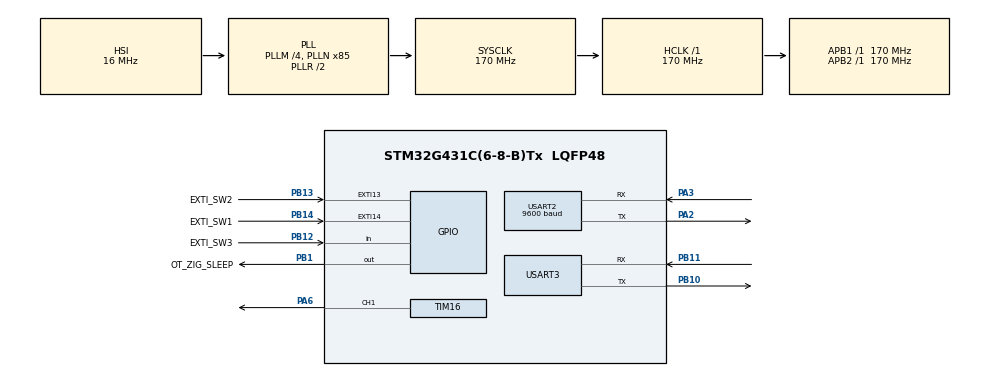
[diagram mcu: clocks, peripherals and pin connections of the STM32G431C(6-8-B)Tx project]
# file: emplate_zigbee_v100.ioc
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Dma.Request0=USART2_RX
Dma.Request1=USART2_TX
Dma.USART2_RX.0.Direction=DMA_PERIPH_TO_MEMORY
Dma.USART2_RX.0.EventEnable=DISABLE
Dma.USART2_RX.0.Instance=DMA1_Channel1
Dma.USART2_RX.0.MemDataAlignment=DMA_MDATAALIGN_BYTE
Dma.USART2_RX.0.MemInc=DMA_MINC_ENABLE
Dma.USART2_RX.0.Mode=DMA_CIRCULAR
Dma.USART2_RX.0.PeriphDataAlignment=DMA_PDATAALIGN_BYTE
Dma.USART2_RX.0.PeriphInc=DMA_PINC_DISABLE
Dma.USART2_RX.0.Polarity=HAL_DMAMUX_REQ_GEN_RISING
Dma.USART2_RX.0.Priority=DMA_PRIORITY_LOW
Dma.USART2_RX.0.RequestNumber=1
Dma.USART2_RX.0.SignalID=NONE
Dma.USART2_RX.0.SyncEnable=DISABLE
Dma.USART2_RX.0.SyncPolarity=HAL_DMAMUX_SYNC_NO_EVENT
Dma.USART2_RX.0.SyncRequestNumber=1
Dma.USART2_RX.0.SyncSignalID=NONE
Dma.USART2_TX.1.Direction=DMA_MEMORY_TO_PERIPH
Dma.USART2_TX.1.EventEnable=DISABLE
Dma.USART2_TX.1.Instance=DMA1_Channel2
Dma.USART2_TX.1.MemDataAlignment=DMA_MDATAALIGN_BYTE
Dma.USART2_TX.1.MemInc=DMA_MINC_ENABLE
Dma.USART2_TX.1.Mode=DMA_NORMAL
Dma.USART2_TX.1.PeriphDataAlignment=DMA_PDATAALIGN_BYTE
Dma.USART2_TX.1.PeriphInc=DMA_PINC_DISABLE
Dma.USART2_TX.1.Polarity=HAL_DMAMUX_REQ_GEN_RISING
Dma.USART2_TX.1.Priority=DMA_PRIORITY_LOW
Dma.USART2_TX.1.RequestNumber=1
Dma.USART2_TX.1.SignalID=NONE
Dma.USART2_TX.1.SyncEnable=DISABLE
Dma.USART2_TX.1.SyncPolarity=HAL_DMAMUX_SYNC_NO_EVENT
Dma.USART2_TX.1.SyncRequestNumber=1
Dma.USART2_TX.1.SyncSignalID=NONE
Mcu.Family=STM32G4
Mcu.Name=STM32G431C(6-8-B)Tx
Mcu.Package=LQFP48
NVIC.DMA1_Channel1_IRQn=true\:1\:0\:true\:false\:true\:false\:true\:true
NVIC.DMA1_Channel2_IRQn=true\:1\:0\:true\:false\:true\:false\:true\:true
NVIC.PriorityGroup=NVIC_PRIORITYGROUP_4
NVIC.TIM7_IRQn=true\:1\:0\:true\:false\:true\:true\:true\:true
NVIC.USART2_IRQn=true\:1\:0\:true\:false\:true\:true\:true\:true
PA13.Mode=Serial_Wire
PA13.Signal=SYS_JTMS-SWDIO
PA14.Mode=Serial_Wire
PA14.Signal=SYS_JTCK-SWCLK
PA2.Mode=Asynchronous
PA2.Signal=USART2_TX
PA3.Mode=Asynchronous
PA3.Signal=USART2_RX
PA6.Signal=S_TIM16_CH1
PB1.GPIO_Label=OT_ZIG_SLEEP
PB1.Signal=GPIO_Output
PB10.Mode=Asynchronous
PB10.Signal=USART3_TX
PB11.Mode=Asynchronous
PB11.Signal=USART3_RX
PB12.GPIO_Label=EXTI_SW3
PB12.Signal=GPIO_Input
PB13.GPIO_Label=EXTI_SW2
PB13.Signal=GPXTI13
PB14.GPIO_Label=EXTI_SW1
PB14.Signal=GPXTI14
PC14-OSC32_IN.Mode=LSE-External-Oscillator
PC14-OSC32_IN.Signal=RCC_OSC32_IN
PC15-OSC32_OUT.Mode=LSE-External-Oscillator
PC15-OSC32_OUT.Signal=RCC_OSC32_OUT
PF0-OSC_IN.Mode=HSE-External-Clock-Source
PF0-OSC_IN.Signal=RCC_OSC_IN
ProjectManager.HeapSize=0x1000
ProjectManager.StackSize=0x1000
ProjectManager.TargetToolchain=STM32CubeIDE
RCC.ADC12Freq_Value=170000000
RCC.AHBFreq_Value=170000000
RCC.APB1Freq_Value=170000000
RCC.APB1TimFreq_Value=170000000
RCC.APB2Freq_Value=170000000
RCC.APB2TimFreq_Value=170000000
RCC.CortexFreq_Value=170000000
RCC.EXTERNAL_CLOCK_VALUE=12288000
RCC.HCLKFreq_Value=170000000
RCC.HSE_VALUE=25000000
RCC.HSI48_VALUE=48000000
RCC.HSI_VALUE=16000000
RCC.PLLM=RCC_PLLM_DIV4
RCC.PLLN=85
RCC.SYSCLKFreq_VALUE=170000000
RCC.SYSCLKSource=RCC_SYSCLKSOURCE_PLLCLK
RCC.USBFreq_Value=170000000
RCC.VCOOutputFreq_Value=340000000
SH.S_TIM16_CH1.0=TIM16_CH1,PWM Generation1 CH1
TIM16.Channel=TIM_CHANNEL_1
TIM16.Prescaler=16
TIM7.PeriodNoDither=999
TIM7.Prescaler=169
USART2.BaudRate=9600
USART2.VirtualMode-Asynchronous=VM_ASYNC
USART3.VirtualMode-Asynchronous=VM_ASYNC
VP_SYS_VS_DBSignals.Mode=DisableDeadBatterySignals
VP_TIM16_VS_ClockSourceINT.Mode=Enable_Timer
VP_TIM7_VS_ClockSourceINT.Mode=Enable_Timer
board=custom

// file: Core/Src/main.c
/* USER CODE BEGIN Header */
/**
  ******************************************************************************
  * @file           : main.c
  * @brief          : Main program body
  ******************************************************************************
  * @attention
  *
  * Copyright (c) 2026 STMicroelectronics.
  * All rights reserved.
  *
  * This software is licensed under terms that can be found in the LICENSE file
  * in the root directory of this software component.
  * If no LICENSE file comes with this software, it is provided AS-IS.
  *
  ******************************************************************************
  */
/* USER CODE END Header */
#include "main.h"

/* USER CODE BEGIN Includes */
#include "user_def.h"
/* USER CODE END Includes */

TIM_HandleTypeDef htim7;
TIM_HandleTypeDef htim16;

UART_HandleTypeDef huart2;
UART_HandleTypeDef huart3;
DMA_HandleTypeDef hdma_usart2_rx;
DMA_HandleTypeDef hdma_usart2_tx;

void SystemClock_Config(void);
static void MX_GPIO_Init(void);
static void MX_DMA_Init(void);
static void MX_TIM7_Init(void);
static void MX_TIM16_Init(void);
static void MX_USART3_UART_Init(void);
static void MX_USART2_UART_Init(void);

int main(void)
{

  /* MCU Configuration--------------------------------------------------------*/

  /* Reset of all peripherals, Initializes the Flash interface and the Systick. */
  HAL_Init();

  /* Configure the system clock */
  SystemClock_Config();

  /* Initialize all configured peripherals */
  MX_GPIO_Init();
  MX_DMA_Init();
  MX_TIM7_Init();
  MX_TIM16_Init();
  MX_USART3_UART_Init();
  MX_USART2_UART_Init();
  /* USER CODE BEGIN 2 */
  run_proc();
  /* USER CODE END 2 */

  /* Infinite loop */
  while (1)
  {

  }
}

void SystemClock_Config(void)
{
  RCC_OscInitTypeDef RCC_OscInitStruct = {0};
  RCC_ClkInitTypeDef RCC_ClkInitStruct = {0};

  /** Configure the main internal regulator output voltage
  */
  HAL_PWREx_ControlVoltageScaling(PWR_REGULATOR_VOLTAGE_SCALE1_BOOST);

  /** Initializes the RCC Oscillators according to the specified parameters
  * in the RCC_OscInitTypeDef structure.
  */
  RCC_OscInitStruct.OscillatorType = RCC_OSCILLATORTYPE_HSI;
  RCC_OscInitStruct.HSIState = RCC_HSI_ON;
  RCC_OscInitStruct.HSICalibrationValue = RCC_HSICALIBRATION_DEFAULT;
  RCC_OscInitStruct.PLL.PLLState = RCC_PLL_ON;
  RCC_OscInitStruct.PLL.PLLSource = RCC_PLLSOURCE_HSI;
  RCC_OscInitStruct.PLL.PLLM = RCC_PLLM_DIV4;
  RCC_OscInitStruct.PLL.PLLN = 85;
  RCC_OscInitStruct.PLL.PLLP = RCC_PLLP_DIV2;
  RCC_OscInitStruct.PLL.PLLQ = RCC_PLLQ_DIV2;
  RCC_OscInitStruct.PLL.PLLR = RCC_PLLR_DIV2;
  if (HAL_RCC_OscConfig(&RCC_OscInitStruct) != HAL_OK)
  {
    Error_Handler();
  }

  /** Initializes the CPU, AHB and APB buses clocks
  */
  RCC_ClkInitStruct.ClockType = RCC_CLOCKTYPE_HCLK|RCC_CLOCKTYPE_SYSCLK
                              |RCC_CLOCKTYPE_PCLK1|RCC_CLOCKTYPE_PCLK2;
  RCC_ClkInitStruct.SYSCLKSource = RCC_SYSCLKSOURCE_PLLCLK;
  RCC_ClkInitStruct.AHBCLKDivider = RCC_SYSCLK_DIV1;
  RCC_ClkInitStruct.APB1CLKDivider = RCC_HCLK_DIV1;
  RCC_ClkInitStruct.APB2CLKDivider = RCC_HCLK_DIV1;

  if (HAL_RCC_ClockConfig(&RCC_ClkInitStruct, FLASH_LATENCY_4) != HAL_OK)
  {
    Error_Handler();
  }
}

static void MX_TIM7_Init(void)
{

  TIM_MasterConfigTypeDef sMasterConfig = {0};

  htim7.Instance = TIM7;
  htim7.Init.Prescaler = 169;
  htim7.Init.CounterMode = TIM_COUNTERMODE_UP;
  htim7.Init.Period = 999;
  htim7.Init.AutoReloadPreload = TIM_AUTORELOAD_PRELOAD_DISABLE;
  if (HAL_TIM_Base_Init(&htim7) != HAL_OK)
  {
    Error_Handler();
  }
  sMasterConfig.MasterOutputTrigger = TIM_TRGO_RESET;
  sMasterConfig.MasterSlaveMode = TIM_MASTERSLAVEMODE_DISABLE;
  if (HAL_TIMEx_MasterConfigSynchronization(&htim7, &sMasterConfig) != HAL_OK)
  {
    Error_Handler();
  }

}

static void MX_TIM16_Init(void)
{

  TIM_OC_InitTypeDef sConfigOC = {0};
  TIM_BreakDeadTimeConfigTypeDef sBreakDeadTimeConfig = {0};

  htim16.Instance = TIM16;
  htim16.Init.Prescaler = 16;
  htim16.Init.CounterMode = TIM_COUNTERMODE_UP;
  htim16.Init.Period = 65535;
  htim16.Init.ClockDivision = TIM_CLOCKDIVISION_DIV1;
  htim16.Init.RepetitionCounter = 0;
  htim16.Init.AutoReloadPreload = TIM_AUTORELOAD_PRELOAD_DISABLE;
  if (HAL_TIM_Base_Init(&htim16) != HAL_OK)
  {
    Error_Handler();
  }
  if (HAL_TIM_PWM_Init(&htim16) != HAL_OK)
  {
    Error_Handler();
  }
  sConfigOC.OCMode = TIM_OCMODE_PWM1;
  sConfigOC.Pulse = 0;
  sConfigOC.OCPolarity = TIM_OCPOLARITY_HIGH;
  sConfigOC.OCNPolarity = TIM_OCNPOLARITY_HIGH;
  sConfigOC.OCFastMode = TIM_OCFAST_DISABLE;
  sConfigOC.OCIdleState = TIM_OCIDLESTATE_RESET;
  sConfigOC.OCNIdleState = TIM_OCNIDLESTATE_RESET;
  if (HAL_TIM_PWM_ConfigChannel(&htim16, &sConfigOC, TIM_CHANNEL_1) != HAL_OK)
  {
    Error_Handler();
  }
  sBreakDeadTimeConfig.OffStateRunMode = TIM_OSSR_DISABLE;
  sBreakDeadTimeConfig.OffStateIDLEMode = TIM_OSSI_DISABLE;
  sBreakDeadTimeConfig.LockLevel = TIM_LOCKLEVEL_OFF;
  sBreakDeadTimeConfig.DeadTime = 0;
  sBreakDeadTimeConfig.BreakState = TIM_BREAK_DISABLE;
  sBreakDeadTimeConfig.BreakPolarity = TIM_BREAKPOLARITY_HIGH;
  sBreakDeadTimeConfig.BreakFilter = 0;
  sBreakDeadTimeConfig.AutomaticOutput = TIM_AUTOMATICOUTPUT_DISABLE;
  if (HAL_TIMEx_ConfigBreakDeadTime(&htim16, &sBreakDeadTimeConfig) != HAL_OK)
  {
    Error_Handler();
  }
  HAL_TIM_MspPostInit(&htim16);

}

static void MX_USART2_UART_Init(void)
{

  huart2.Instance = USART2;
  huart2.Init.BaudRate = 9600;
  huart2.Init.WordLength = UART_WORDLENGTH_8B;
  huart2.Init.StopBits = UART_STOPBITS_1;
  huart2.Init.Parity = UART_PARITY_NONE;
  huart2.Init.Mode = UART_MODE_TX_RX;
  huart2.Init.HwFlowCtl = UART_HWCONTROL_NONE;
  huart2.Init.OverSampling = UART_OVERSAMPLING_16;
  huart2.Init.OneBitSampling = UART_ONE_BIT_SAMPLE_DISABLE;
  huart2.Init.ClockPrescaler = UART_PRESCALER_DIV1;
  huart2.AdvancedInit.AdvFeatureInit = UART_ADVFEATURE_NO_INIT;
  if (HAL_UART_Init(&huart2) != HAL_OK)
  {
    Error_Handler();
  }
  if (HAL_UARTEx_SetTxFifoThreshold(&huart2, UART_TXFIFO_THRESHOLD_1_8) != HAL_OK)
  {
    Error_Handler();
  }
  if (HAL_UARTEx_SetRxFifoThreshold(&huart2, UART_RXFIFO_THRESHOLD_1_8) != HAL_OK)
  {
    Error_Handler();
  }
  if (HAL_UARTEx_DisableFifoMode(&huart2) != HAL_OK)
  {
    Error_Handler();
  }

}

static void MX_USART3_UART_Init(void)
{

  huart3.Instance = USART3;
  huart3.Init.BaudRate = 115200;
  huart3.Init.WordLength = UART_WORDLENGTH_8B;
  huart3.Init.StopBits = UART_STOPBITS_1;
  huart3.Init.Parity = UART_PARITY_NONE;
  huart3.Init.Mode = UART_MODE_TX_RX;
  huart3.Init.HwFlowCtl = UART_HWCONTROL_NONE;
  huart3.Init.OverSampling = UART_OVERSAMPLING_16;
  huart3.Init.OneBitSampling = UART_ONE_BIT_SAMPLE_DISABLE;
  huart3.Init.ClockPrescaler = UART_PRESCALER_DIV1;
  huart3.AdvancedInit.AdvFeatureInit = UART_ADVFEATURE_NO_INIT;
  if (HAL_UART_Init(&huart3) != HAL_OK)
  {
    Error_Handler();
  }
  if (HAL_UARTEx_SetTxFifoThreshold(&huart3, UART_TXFIFO_THRESHOLD_1_8) != HAL_OK)
  {
    Error_Handler();
  }
  if (HAL_UARTEx_SetRxFifoThreshold(&huart3, UART_RXFIFO_THRESHOLD_1_8) != HAL_OK)
  {
    Error_Handler();
  }
  if (HAL_UARTEx_DisableFifoMode(&huart3) != HAL_OK)
  {
    Error_Handler();
  }

}

static void MX_DMA_Init(void)
{

  /* DMA controller clock enable */
  __HAL_RCC_DMAMUX1_CLK_ENABLE();
  __HAL_RCC_DMA1_CLK_ENABLE();

  /* DMA interrupt init */
  /* DMA1_Channel1_IRQn interrupt configuration */
  HAL_NVIC_SetPriority(DMA1_Channel1_IRQn, 1, 0);
  HAL_NVIC_EnableIRQ(DMA1_Channel1_IRQn);
  /* DMA1_Channel2_IRQn interrupt configuration */
  HAL_NVIC_SetPriority(DMA1_Channel2_IRQn, 1, 0);
  HAL_NVIC_EnableIRQ(DMA1_Channel2_IRQn);

}

static void MX_GPIO_Init(void)
{
  GPIO_InitTypeDef GPIO_InitStruct = {0};

  /* GPIO Ports Clock Enable */
  __HAL_RCC_GPIOC_CLK_ENABLE();
  __HAL_RCC_GPIOF_CLK_ENABLE();
  __HAL_RCC_GPIOA_CLK_ENABLE();
  __HAL_RCC_GPIOB_CLK_ENABLE();

  /*Configure GPIO pin Output Level */
  HAL_GPIO_WritePin(OT_ZIG_SLEEP_GPIO_Port, OT_ZIG_SLEEP_Pin, GPIO_PIN_RESET);

  /*Configure GPIO pin : OT_ZIG_SLEEP_Pin */
  GPIO_InitStruct.Pin = OT_ZIG_SLEEP_Pin;
  GPIO_InitStruct.Mode = GPIO_MODE_OUTPUT_PP;
  GPIO_InitStruct.Pull = GPIO_NOPULL;
  GPIO_InitStruct.Speed = GPIO_SPEED_FREQ_LOW;
  HAL_GPIO_Init(OT_ZIG_SLEEP_GPIO_Port, &GPIO_InitStruct);

  /*Configure GPIO pin : EXTI_SW3_Pin */
  GPIO_InitStruct.Pin = EXTI_SW3_Pin;
  GPIO_InitStruct.Mode = GPIO_MODE_INPUT;
  GPIO_InitStruct.Pull = GPIO_NOPULL;
  HAL_GPIO_Init(EXTI_SW3_GPIO_Port, &GPIO_InitStruct);

  /*Configure GPIO pins : EXTI_SW2_Pin EXTI_SW1_Pin */
  GPIO_InitStruct.Pin = EXTI_SW2_Pin|EXTI_SW1_Pin;
  GPIO_InitStruct.Mode = GPIO_MODE_IT_RISING;
  GPIO_InitStruct.Pull = GPIO_NOPULL;
  HAL_GPIO_Init(GPIOB, &GPIO_InitStruct);

}

void Error_Handler(void)
{
  __disable_irq();
  while (1)
  {
  }
}
